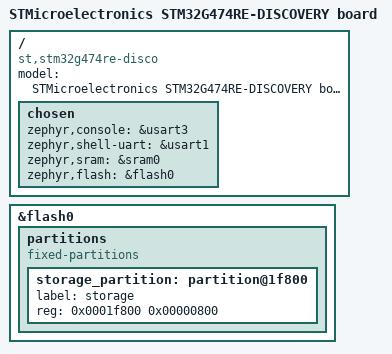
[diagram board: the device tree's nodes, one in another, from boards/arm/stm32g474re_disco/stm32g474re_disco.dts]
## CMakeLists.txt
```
# SPDX-License-Identifier: Apache-2.0

cmake_minimum_required(VERSION 3.13.1)

set(PROJ_ROOT ${CMAKE_CURRENT_SOURCE_DIR}/)
set(DTS_ROOT ${CMAKE_CURRENT_SOURCE_DIR}/dts)
set(DTC_OVERLAY_FILE "boards/stm32g474re_disco.overlay")

set(BOARD_ROOT ${CMAKE_CURRENT_LIST_DIR})
set(BOARD stm32g474re_disco)

find_package(Zephyr REQUIRED HINTS $ENV{ZEPHYR_BASE})
project(shell_m2m)

target_sources(app PRIVATE src/main.c)
```

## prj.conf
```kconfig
CONFIG_PRINTK=y
CONFIG_LOG=y

CONFIG_SHELL=y

CONFIG_SHELL_BACKEND_SERIAL=y

# Below 2 configurations and very important for m2m communication
# Turn off the SHELL_LOG_BACKEND so that logs don't get redirected to the shell transport layer
# Then log backend uart has to be explicitly turned on 
CONFIG_SHELL_LOG_BACKEND=n
CONFIG_LOG_BACKEND_UART=y

# Disable to prompt and command echo
CONFIG_SHELL_PROMPT_UART=""
CONFIG_SHELL_ECHO_STATUS=n

CONFIG_INIT_STACKS=y
CONFIG_KERNEL_SHELL=n

CONFIG_THREAD_MONITOR=y
CONFIG_THREAD_NAME=y
#CONFIG_THREAD_STACK_INFO=y

# To disable the boot message printed on the console, uncomment the following line
#CONFIG_BOOT_BANNER=n

CONFIG_DEVICE_SHELL=n
CONFIG_POSIX_CLOCK=n
CONFIG_DATE_SHELL=n
CONFIG_SENSOR_SHELL=n
CONFIG_THREAD_RUNTIME_STATS=n

CONFIG_SHELL_HISTORY=n
CONFIG_SHELL_STACK_SIZE=1024
CONFIG_SHELL_CMD_BUFF_SIZE=128
CONFIG_SHELL_WILDCARD=n
CONFIG_SHELL_DYNAMIC_CMDS=n
CONFIG_SHELL_VT100_COLORS=n
CONFIG_SHELL_HELP_ON_WRONG_ARGUMENT_COUNT=n
CONFIG_SHELL_STATS=n
CONFIG_SHELL_CMDS=n
CONFIG_SHELL_HELP=n
CONFIG_SHELL_TAB=n
CONFIG_SHELL_METAKEYS=n
```

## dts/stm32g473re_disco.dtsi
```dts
/*
 * Copyright (c) 2020 Rohan Dey
 *
 * SPDX-License-Identifier: Apache-2.0
 */

#include <stm32g473re_disco_usart3.dtsi>
#include <stm32g473re_disco_usart1.dtsi>
```

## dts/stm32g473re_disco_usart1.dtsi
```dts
/*
 * Copyright (c) 2020 Rohan Dey
 *
 * SPDX-License-Identifier: Apache-2.0
 */
 
&pinctrl {
	usart1_tx: gpioc_4 {
		pinmux = <STM32_PINMUX('C', 4, AF7)>;
	};
	
	usart1_rx: gpioc_5 {
		pinmux = <STM32_PINMUX('C', 5, AF7)>;
	};
};
 

&usart1 {
    status = "okay";
    current-speed = <115200>;
    pinctrl-0 = <&usart1_tx &usart1_rx>;
};
```

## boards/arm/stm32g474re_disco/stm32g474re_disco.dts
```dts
/*
 * Copyright (c) 2019 STMicroelectronics.
 *
 * SPDX-License-Identifier: Apache-2.0
 */

/dts-v1/;
#include <st/g4/stm32g473Xe.dtsi>
#include <st/g4/stm32g474r(b-c-e)tx-pinctrl.dtsi>
#include <stm32g473re_disco.dtsi>

/ {
	model = "STMicroelectronics STM32G474RE-DISCOVERY board";
	compatible = "st,stm32g474re-disco";

	chosen {
		zephyr,console = &usart3;
		zephyr,shell-uart = &usart1;
		zephyr,sram = &sram0;
		zephyr,flash = &flash0;
	};
};

&flash0 {
	/*
	 * For more information, see:
	 * http://docs.zephyrproject.org/latest/guides/dts/index.html#flash-partitions
	 */
	partitions {
		compatible = "fixed-partitions";
		#address-cells = <1>;
		#size-cells = <1>;

		/* Set 2Kb of storage at the end of the 128Kb of flash */
		storage_partition: partition@1f800 {
			label = "storage";
			reg = <0x0001f800 0x00000800>;
		};
	};
};
```

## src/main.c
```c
#include <zephyr.h>
#include <sys/printk.h>
#include <shell/shell.h>
#include <version.h>
#include <logging/log.h>
#include <stdlib.h>

LOG_MODULE_REGISTER(app);

static int cmd_version(const struct shell *shell, size_t argc, char **argv)
{
	ARG_UNUSED(argc);
	ARG_UNUSED(argv);

	/* Log messages to be printed on the console */
	LOG_INF("cmd_version received");
	LOG_INF("responding: [Zephyr version %s]", KERNEL_VERSION_STRING);
//	printk("1.2.3.4");

	/* Response of the command, to be printed on the shell */
	shell_print(shell, "Zephyr version %s", KERNEL_VERSION_STRING);
//	shell_print(shell, "1.2.3.4");

	return 0;
}

SHELL_CMD_ARG_REGISTER(version, NULL, "Show kernel version", cmd_version, 1, 0);

void main(void)
{
	/* Log messages to be printed on the console */
	LOG_INF("Starting shell m2m application");

	while (1) {
		// Do nothing ...
		k_sleep(K_MSEC(2000));
	}
}
```
